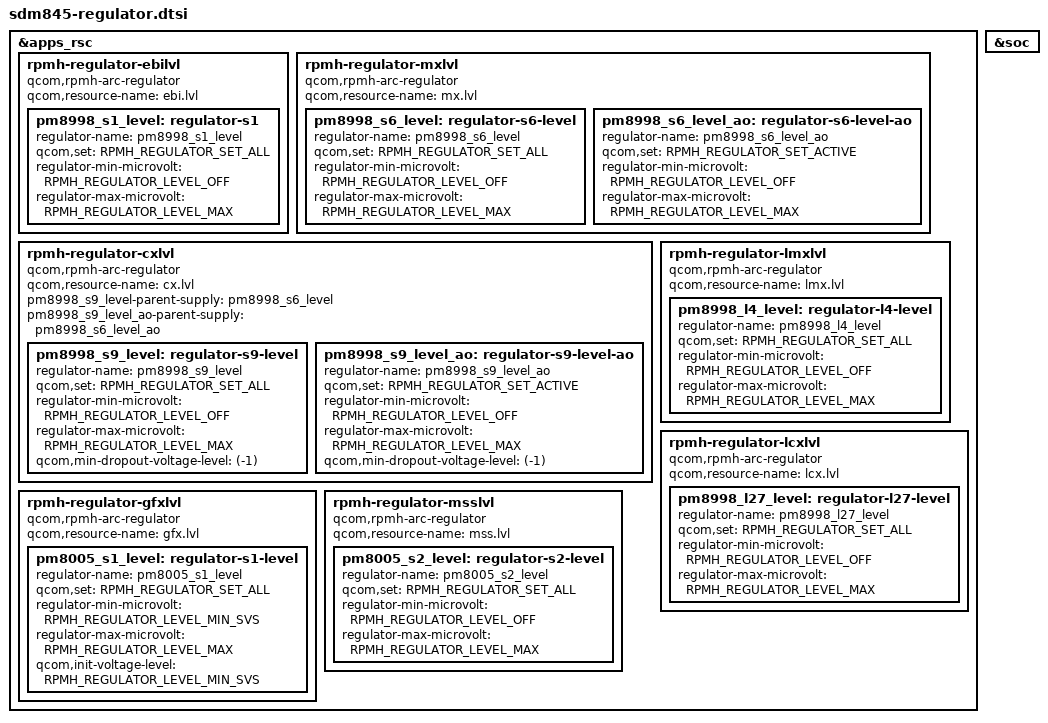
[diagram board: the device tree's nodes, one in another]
/* Copyright (c) 2016-2018, The Linux Foundation. All rights reserved.
 *
 * This program is free software; you can redistribute it and/or modify
 * it under the terms of the GNU General Public License version 2 and
 * only version 2 as published by the Free Software Foundation.
 *
 * This program is distributed in the hope that it will be useful,
 * but WITHOUT ANY WARRANTY; without even the implied warranty of
 * MERCHANTABILITY or FITNESS FOR A PARTICULAR PURPOSE.  See the
 * GNU General Public License for more details.
 */

#include <dt-bindings/gpio/gpio.h>
#include <dt-bindings/regulator/qcom,rpmh-regulator-downstream.h>

&apps_rsc {
	/* PM8998 S1 = VDD_EBI supply */
	rpmh-regulator-ebilvl {
		compatible = "qcom,rpmh-arc-regulator";
		qcom,resource-name = "ebi.lvl";
		pm8998_s1_level: regulator-s1 {
			regulator-name = "pm8998_s1_level";
			qcom,set = <RPMH_REGULATOR_SET_ALL>;
			regulator-min-microvolt = <RPMH_REGULATOR_LEVEL_OFF>;
			regulator-max-microvolt = <RPMH_REGULATOR_LEVEL_MAX>;
		};
	};

	/* PM8998 S6 = VDD_MX supply */
	rpmh-regulator-mxlvl {
		compatible = "qcom,rpmh-arc-regulator";
		qcom,resource-name = "mx.lvl";
		pm8998_s6_level: regulator-s6-level {
			regulator-name = "pm8998_s6_level";
			qcom,set = <RPMH_REGULATOR_SET_ALL>;
			regulator-min-microvolt = <RPMH_REGULATOR_LEVEL_OFF>;
			regulator-max-microvolt = <RPMH_REGULATOR_LEVEL_MAX>;
		};

		pm8998_s6_level_ao: regulator-s6-level-ao {
			regulator-name = "pm8998_s6_level_ao";
			qcom,set = <RPMH_REGULATOR_SET_ACTIVE>;
			regulator-min-microvolt = <RPMH_REGULATOR_LEVEL_OFF>;
			regulator-max-microvolt = <RPMH_REGULATOR_LEVEL_MAX>;
		};
	};

	/* PM8998 S9 + S8 = VDD_CX supply */
	rpmh-regulator-cxlvl {
		compatible = "qcom,rpmh-arc-regulator";
		qcom,resource-name = "cx.lvl";
		pm8998_s9_level-parent-supply = <&pm8998_s6_level>;
		pm8998_s9_level_ao-parent-supply = <&pm8998_s6_level_ao>;
		pm8998_s9_level: regulator-s9-level {
			regulator-name = "pm8998_s9_level";
			qcom,set = <RPMH_REGULATOR_SET_ALL>;
			regulator-min-microvolt = <RPMH_REGULATOR_LEVEL_OFF>;
			regulator-max-microvolt = <RPMH_REGULATOR_LEVEL_MAX>;
			qcom,min-dropout-voltage-level = <(-1)>;
		};

		pm8998_s9_level_ao: regulator-s9-level-ao {
			regulator-name = "pm8998_s9_level_ao";
			qcom,set = <RPMH_REGULATOR_SET_ACTIVE>;
			regulator-min-microvolt = <RPMH_REGULATOR_LEVEL_OFF>;
			regulator-max-microvolt = <RPMH_REGULATOR_LEVEL_MAX>;
			qcom,min-dropout-voltage-level = <(-1)>;
		};
	};

	/* PM8998 L4 = VDD_SSC_MX supply */
	rpmh-regulator-lmxlvl {
		compatible = "qcom,rpmh-arc-regulator";
		qcom,resource-name = "lmx.lvl";
		pm8998_l4_level: regulator-l4-level {
			regulator-name = "pm8998_l4_level";
			qcom,set = <RPMH_REGULATOR_SET_ALL>;
			regulator-min-microvolt = <RPMH_REGULATOR_LEVEL_OFF>;
			regulator-max-microvolt = <RPMH_REGULATOR_LEVEL_MAX>;
		};
	};

	/* PM8998 L27 = VDD_SSC_CX supply */
	rpmh-regulator-lcxlvl {
		compatible = "qcom,rpmh-arc-regulator";
		qcom,resource-name = "lcx.lvl";
		pm8998_l27_level: regulator-l27-level {
			regulator-name = "pm8998_l27_level";
			qcom,set = <RPMH_REGULATOR_SET_ALL>;
			regulator-min-microvolt = <RPMH_REGULATOR_LEVEL_OFF>;
			regulator-max-microvolt = <RPMH_REGULATOR_LEVEL_MAX>;
		};
	};

	/* PM8005 S1 + S4 = 2 phase VDD_GFX supply */
	rpmh-regulator-gfxlvl {
		compatible = "qcom,rpmh-arc-regulator";
		qcom,resource-name = "gfx.lvl";
		pm8005_s1_level: regulator-s1-level {
			regulator-name = "pm8005_s1_level";
			qcom,set = <RPMH_REGULATOR_SET_ALL>;
			regulator-min-microvolt
				= <RPMH_REGULATOR_LEVEL_MIN_SVS>;
			regulator-max-microvolt
				= <RPMH_REGULATOR_LEVEL_MAX>;
			qcom,init-voltage-level
				= <RPMH_REGULATOR_LEVEL_MIN_SVS>;
		};
	};

	/* PM8005 S2 = VDD_MODEM supply */
	rpmh-regulator-msslvl {
		compatible = "qcom,rpmh-arc-regulator";
		qcom,resource-name = "mss.lvl";
		pm8005_s2_level: regulator-s2-level {
			regulator-name = "pm8005_s2_level";
			qcom,set = <RPMH_REGULATOR_SET_ALL>;
			regulator-min-microvolt = <RPMH_REGULATOR_LEVEL_OFF>;
			regulator-max-microvolt = <RPMH_REGULATOR_LEVEL_MAX>;
		};
	};
};

&soc {
	//ext_5v_boost: ext_5v_boost {
		//status = "disabled";
		//compatible = "regulator-fixed";
		//regulator-name = "ext_5v_boost";
		//gpio = <&pmi8998_gpios 10 GPIO_ACTIVE_HIGH>;
		//enable-active-high;

		//regulator-enable-ramp-delay = <1600>;
		//pinctrl-names = "default";
		//pinctrl-0 = <&usb2_ext_5v_boost_default>;
	//};
};
